# ATxmega128A1 register map
Vendor: Atmel; File version: 1.0
CPU: other r0p0, little endian, no MPU, no FPU, 4 interrupt priority bits
Registers are 8-bit, read-write, reset 0x0 unless marked. A register's access mark holds for its fields unless they carry their own. Offsets are from the block's base; [hi:lo] are bit positions; lines under a group give offsets from that group; {n}, {i} and the like mark numbered series.

## ADCA — Analog/Digital Converter
Base 0x00000200
Same registers: ADCB 0x00000240
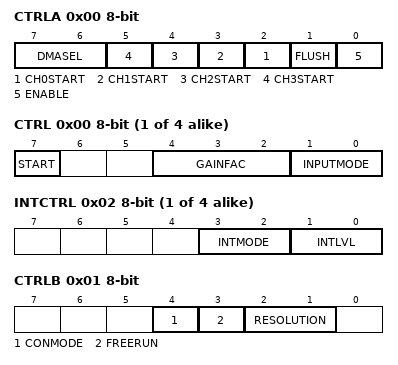
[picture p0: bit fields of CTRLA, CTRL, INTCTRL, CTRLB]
0x00 CTRLA — Control Register A
  [7:6] DMASEL — DMA Selection
    0=OFF (Combined DMA request OFF); 1=CH01 (ADC Channel 0 or 1); 2=CH012 (ADC Channel 0 or 1 or 2); 3=CH0123 (ADC Channel 0 or 1 or 2 or 3)
  [n+2] CH{n}START (n=0..3) — Channel {n} Start Conversion
  [1] FLUSH — Flush Pipeline
  [0] ENABLE — Enable ADC
0x00 CH{i} group (i=0..3) — ADC Channel
  0x00 CTRL — Control Register
    [7] START — Channel Start Conversion
    [4:2] GAINFAC — Gain Factor
      0=1x gain; 1=2X (2x gain); 2=4X (4x gain); 3=8X (8x gain); 4=16X (16x gain); 5=32X (32x gain); 6=64X (64x gain); 7=DIV2 (x/2 gain)
    [1:0] INPUTMODE — Input Mode Select
      0=INTERNAL (Internal inputs, no gain); 1=SINGLEENDED (Single-ended input, no gain); 2=DIFF (Differential input, no gain); 3=DIFFWGAIN (Differential input, with gain)
  0x01 MUXCTRL — MUX Control
    [6:3] MUXINT — Internal Input Select
      0=TEMP (Temperature Reference); 1=BANDGAP (Bandgap Reference); 2=SCALEDVCC (1/10 scaled VCC); 3=DAC (DAC output)
    [6:3] MUXPOS — Positive Input Select
      {v}=PIN{v} (Input pin {v}) (v=0..7)
    [1:0] MUXNEG — Negative Input Select
      0=PIN0 (Input pin 0); 0=PIN4 (Input pin 4); 1=PIN1 (Input pin 1); 1=PIN5 (Input pin 5); 2=PIN2 (Input pin 2); 2=PIN6 (Input pin 6); 3=PIN3 (Input pin 3); 3=PIN7 (Input pin 7)
    [1:0] MUXNEGH — MUX selection on Negative ADC Input Gain on 4 MSB pins
      {v}=PIN{v+4} (Input pin {v+4}) (v=0..3)
    [1:0] MUXNEGL — MUX selection on Negative ADC Input Gain on 4 LSB pins
      {v}=PIN{v} (Input pin {v}) (v=0..3)
  0x02 INTCTRL — Channel Interrupt Control
    [3:2] INTMODE — Interrupt Mode
      0=COMPLETE (Interrupt on conversion complete); 1=BELOW (Interrupt on result below compare value); 3=ABOVE (Interrupt on result above compare value)
    [1:0] INTLVL — Interrupt Level
      0=OFF (Interrupt disabled); 1=LO (Low level); 2=MED (Medium level); 3=HI (High level)
  0x03 INTFLAGS — Interrupt Flags
    [0] CHIF — Channel Interrupt Flag
  0x04 RES 16-bit (reset mask 0xFF) — Channel Result
0x01 CTRLB — Control Register B
  [4] CONMODE — Conversion Mode
  [3] FREERUN — Free Running Mode Enable
  [2:1] RESOLUTION — Result Resolution
    0=12BIT (12-bit right-adjusted result); 2=8BIT (8-bit right-adjusted result); 3=LEFT12BIT (12-bit left-adjusted result)
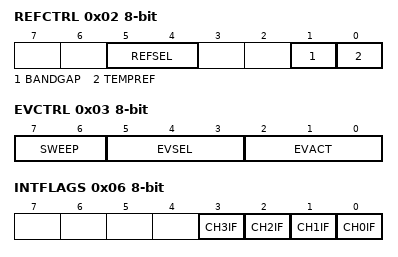
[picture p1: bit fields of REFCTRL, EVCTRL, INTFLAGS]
0x02 REFCTRL — Reference Control
  [5:4] REFSEL — Reference Selection
    0=INT1V (Internal 1V); 1=INTVCC (Internal VCC / 1.6V); 2=AREFA (External reference on PORT A); 3=AREFB (External reference on PORT B)
  [1] BANDGAP — Bandgap enable
  [0] TEMPREF — Temperature Reference Enable
0x03 EVCTRL — Event Control
  [7:6] SWEEP — Channel Sweep Selection
    0=ADC Channel 0; 1=ADC Channel 0,1; 2=ADC Channel 0,1,2; 3=ADC Channel 0,1,2,3
  [5:3] EVSEL — Event Input Select
    {v}=Event Channel {v},{v+1},{v+2},{v+3} (v=0..4); 5=Event Channel 5,6,7; 6=Event Channel 6,7; 7=Event Channel 7
  [2:0] EVACT — Event Action Select
    0=NONE (No event action); 1=CH0 (First event triggers channel 0); 2=CH01 (First two events trigger channel 0,1); 3=CH012 (First three events trigger channel 0,1,2); 4=CH0123 (Events trigger channel 0,1,2,3); 5=SWEEP (First event triggers sweep); 6=SYNCSWEEP (The ADC is flushed and restarted for accurate timing)
0x04 PRESCALER — Clock Prescaler
  [2:0] PRESCALER — Clock Prescaler Selection
    0=DIV4 (Divide clock by 4); 1=DIV8 (Divide clock by 8); 2=DIV16 (Divide clock by 16); 3=DIV32 (Divide clock by 32); 4=DIV64 (Divide clock by 64); 5=DIV128 (Divide clock by 128); 6=DIV256 (Divide clock by 256); 7=DIV512 (Divide clock by 512)
0x06 INTFLAGS — Interrupt Flags
  [n] CH{n}IF (n=0..3) — Channel {n} Interrupt Flag
0x07 TEMP — Temporary register
0x0C CAL 16-bit (reset mask 0xFF) — Calibration Value
{0x10+2i} CH{i}RES 16-bit (reset mask 0xFF) (i=0..3) — Channel {i} Result
0x18 CMP 16-bit (reset mask 0xFF) — Compare Value
